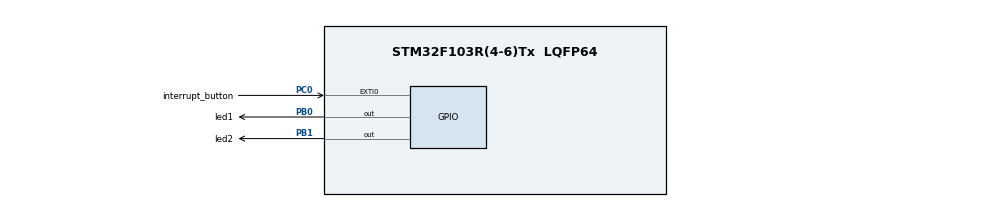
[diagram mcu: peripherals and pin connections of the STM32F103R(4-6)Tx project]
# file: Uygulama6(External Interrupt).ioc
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Mcu.Family=STM32F1
Mcu.Name=STM32F103R(4-6)Tx
Mcu.Package=LQFP64
NVIC.EXTI0_IRQn=true\:0\:0\:false\:false\:true\:true\:true
NVIC.PriorityGroup=NVIC_PRIORITYGROUP_4
PB0.GPIO_Label=led1
PB0.GPIO_Speed=GPIO_SPEED_FREQ_MEDIUM
PB0.Signal=GPIO_Output
PB1.GPIO_Label=led2
PB1.GPIO_Speed=GPIO_SPEED_FREQ_MEDIUM
PB1.Signal=GPIO_Output
PC0.GPIO_Label=interrupt_button
PC0.GPIO_ModeDefaultEXTI=GPIO_MODE_IT_RISING
PC0.GPIO_PuPd=GPIO_PULLDOWN
PC0.Signal=GPXTI0
ProjectManager.HeapSize=0x200
ProjectManager.StackSize=0x400
ProjectManager.TargetToolchain=MDK-ARM V5.27
RCC.APB1Freq_Value=8000000
RCC.APB2Freq_Value=8000000
VP_SYS_VS_ND.Mode=No_Debug
board=custom

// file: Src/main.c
/* USER CODE BEGIN Header */
/**
  ******************************************************************************
  * @file           : main.c
  * @brief          : Main program body
  ******************************************************************************
  * @attention
  *
  * <h2><center>&copy; Copyright (c) 2020 STMicroelectronics.
  * All rights reserved.</center></h2>
  *
  * This software component is licensed by ST under BSD 3-Clause license,
  * the "License"; You may not use this file except in compliance with the
  * License. You may obtain a copy of the License at:
  *                        opensource.org/licenses/BSD-3-Clause
  *
  ******************************************************************************
  */
/* USER CODE END Header */

#include "main.h"

void SystemClock_Config(void);
static void MX_GPIO_Init(void);

int main(void)
{

  /* MCU Configuration--------------------------------------------------------*/

  /* Reset of all peripherals, Initializes the Flash interface and the Systick. */
  HAL_Init();

  /* Configure the system clock */
  SystemClock_Config();

  /* Initialize all configured peripherals */
  MX_GPIO_Init();

  /* Infinite loop */
  while (1)
  {

    /* USER CODE BEGIN 3 */
		HAL_GPIO_TogglePin(GPIOB,led1_Pin| led2_Pin);
		HAL_Delay(800);
  }
  /* USER CODE END 3 */
}

void SystemClock_Config(void)
{
  RCC_OscInitTypeDef RCC_OscInitStruct = {0};
  RCC_ClkInitTypeDef RCC_ClkInitStruct = {0};

  /** Initializes the CPU, AHB and APB busses clocks
  */
  RCC_OscInitStruct.OscillatorType = RCC_OSCILLATORTYPE_HSI;
  RCC_OscInitStruct.HSIState = RCC_HSI_ON;
  RCC_OscInitStruct.HSICalibrationValue = RCC_HSICALIBRATION_DEFAULT;
  RCC_OscInitStruct.PLL.PLLState = RCC_PLL_NONE;
  if (HAL_RCC_OscConfig(&RCC_OscInitStruct) != HAL_OK)
  {
    Error_Handler();
  }
  /** Initializes the CPU, AHB and APB busses clocks
  */
  RCC_ClkInitStruct.ClockType = RCC_CLOCKTYPE_HCLK|RCC_CLOCKTYPE_SYSCLK
                              |RCC_CLOCKTYPE_PCLK1|RCC_CLOCKTYPE_PCLK2;
  RCC_ClkInitStruct.SYSCLKSource = RCC_SYSCLKSOURCE_HSI;
  RCC_ClkInitStruct.AHBCLKDivider = RCC_SYSCLK_DIV1;
  RCC_ClkInitStruct.APB1CLKDivider = RCC_HCLK_DIV1;
  RCC_ClkInitStruct.APB2CLKDivider = RCC_HCLK_DIV1;

  if (HAL_RCC_ClockConfig(&RCC_ClkInitStruct, FLASH_LATENCY_0) != HAL_OK)
  {
    Error_Handler();
  }
}

static void MX_GPIO_Init(void)
{
  GPIO_InitTypeDef GPIO_InitStruct = {0};

  /* GPIO Ports Clock Enable */
  __HAL_RCC_GPIOC_CLK_ENABLE();
  __HAL_RCC_GPIOB_CLK_ENABLE();

  /*Configure GPIO pin Output Level */
  HAL_GPIO_WritePin(GPIOB, led1_Pin|led2_Pin, GPIO_PIN_RESET);

  /*Configure GPIO pin : interrupt_button_Pin */
  GPIO_InitStruct.Pin = interrupt_button_Pin;
  GPIO_InitStruct.Mode = GPIO_MODE_IT_RISING;
  GPIO_InitStruct.Pull = GPIO_PULLDOWN;
  HAL_GPIO_Init(interrupt_button_GPIO_Port, &GPIO_InitStruct);

  /*Configure GPIO pins : led1_Pin led2_Pin */
  GPIO_InitStruct.Pin = led1_Pin|led2_Pin;
  GPIO_InitStruct.Mode = GPIO_MODE_OUTPUT_PP;
  GPIO_InitStruct.Pull = GPIO_NOPULL;
  GPIO_InitStruct.Speed = GPIO_SPEED_FREQ_MEDIUM;
  HAL_GPIO_Init(GPIOB, &GPIO_InitStruct);

  /* EXTI interrupt init*/
  HAL_NVIC_SetPriority(EXTI0_IRQn, 0, 0);
  HAL_NVIC_EnableIRQ(EXTI0_IRQn);

}

// interrupt kismi burasi 2 yol var ,callback yolu ,2.inci yol ise stm32f1xx_it.c  de line 203 e bak

/* USER CODE BEGIN 4 */

//void HAL_GPIO_EXTI_Callback(uint16_t GPIO_Pin){ // functions da stm32f1xx_hal_gpio.c den bulduk
//
//  UNUSED(GPIO_Pin);
//	HAL_GPIO_WritePin(GPIOB,led1_Pin|led2_Pin,GPIO_PIN_SET); // interrupt oldugunda ledleri sonduruyor , cubemx de  low yaptik  properties deki ilk özelligi o yüzden set de ledler söner, high yapsaydin  reset ile sönerdi
//
//}

/* USER CODE END 4 */

void Error_Handler(void)
{
}

/************************ (C) COPYRIGHT STMicroelectronics *****END OF FILE****/
